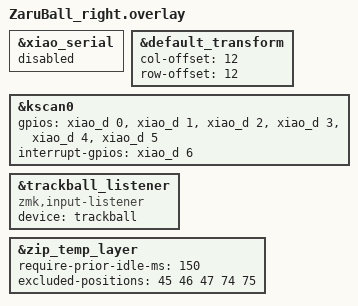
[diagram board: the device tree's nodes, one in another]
#include "ZaruBall.dtsi"
#include <dt-bindings/zmk/input_transform.h>

&xiao_serial { status = "disabled"; };

// matrix transformでのピン数オフセット
&default_transform { // Offset of 7 because the left side has 2 columns
    col-offset = <12>;
    row-offset = <12>;
};

&kscan0 {
    gpios
        = <&xiao_d 0 GPIO_ACTIVE_HIGH>//M1
        , <&xiao_d 1 GPIO_ACTIVE_HIGH>//M2
        , <&xiao_d 2 GPIO_ACTIVE_HIGH>//M3
        , <&xiao_d 3 GPIO_ACTIVE_HIGH>//M4
        , <&xiao_d 4 GPIO_ACTIVE_HIGH>//M5
        , <&xiao_d 5 GPIO_ACTIVE_HIGH>//M6
        ;
    interrupt-gpios = <&xiao_d 6 (GPIO_ACTIVE_HIGH | GPIO_PULL_DOWN)>;//IGPIO
};

// pmw-3610
&trackball_listener {
    status = "okay";
    compatible = "zmk,input-listener";
    device = <&trackball>;
};

/* ========================================================================== */
/* 最新ZMK仕様に合わせた追加部分                                                */
/* ========================================================================== */

&zip_temp_layer {
    /* 【振動対策】キー入力があった後、何ミリ秒間トラックボールの自動レイヤー移動を禁止するか */
    /* タイピングの微振動での誤作動を防ぐため、150〜200ms 程度をセットします */
    require-prior-idle-ms = <150>;

    /* 【レイヤー抜け対策】特定のキーが押されている間は、タイムアウトを無視してマウスレイヤーを維持 */
    excluded-positions = <
        45 // J
        46 // K
        47 // L
        74 // 3
        75 // 4
    >;
};
